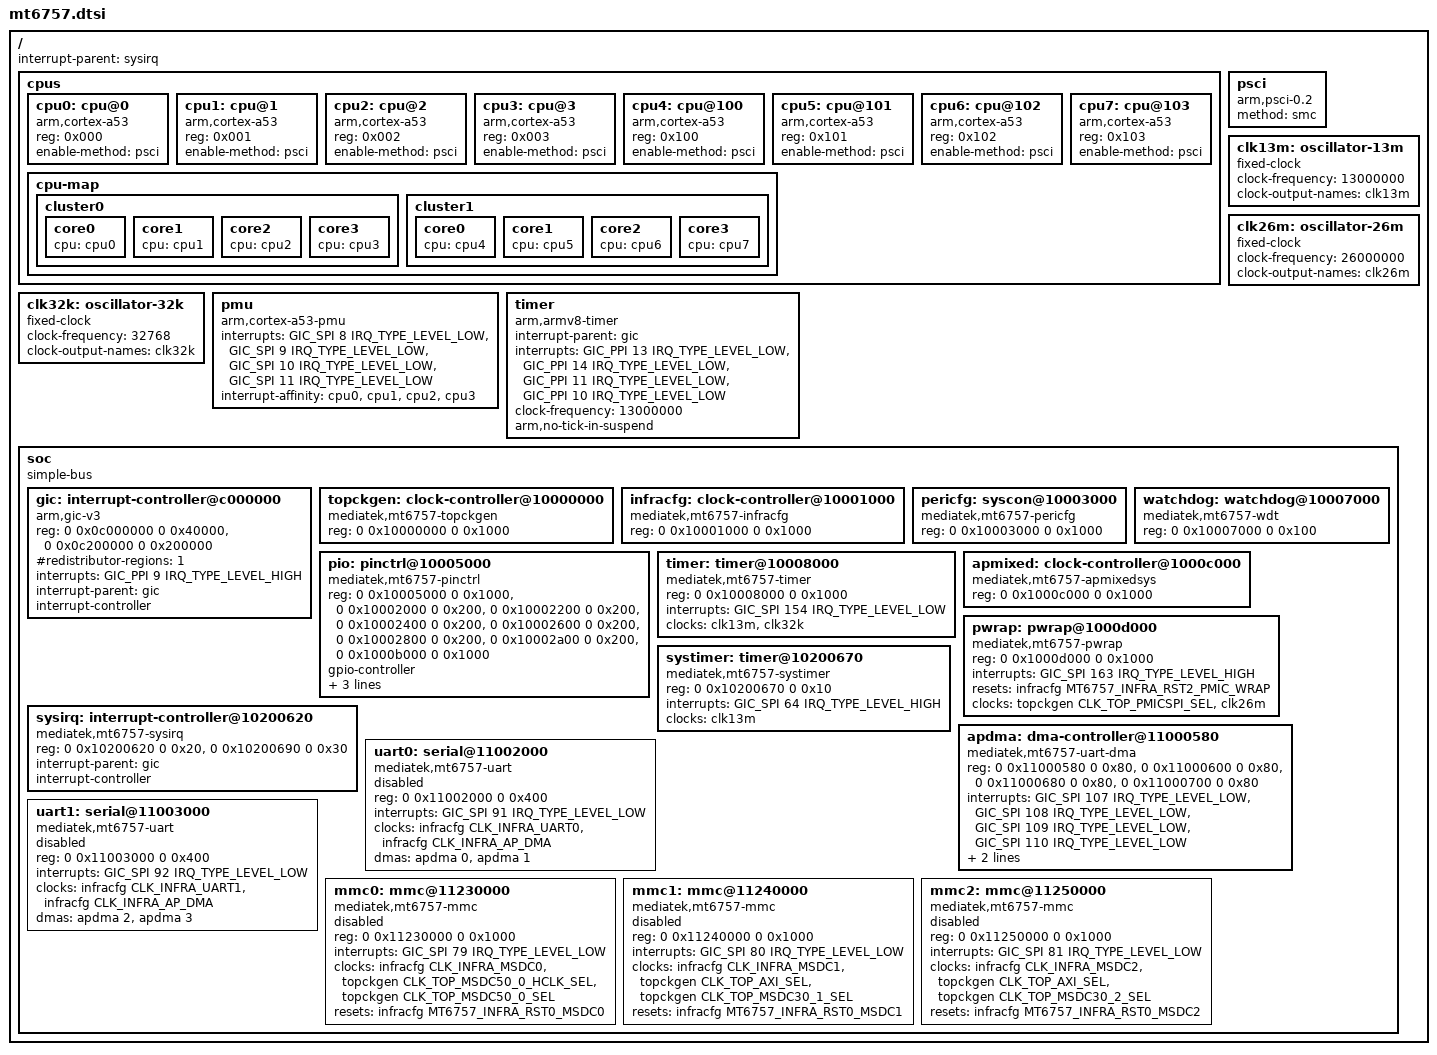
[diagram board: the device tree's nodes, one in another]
// SPDX-License-Identifier: GPL-2.0-only
/*
 * Copyright (c) 2025 Ben Grisdale <bengris32@protonmail.ch>
 */

#include <dt-bindings/interrupt-controller/arm-gic.h>

#include <dt-bindings/clock/mediatek,mt6757-apmixedsys.h>
#include <dt-bindings/clock/mediatek,mt6757-infracfg.h>
#include <dt-bindings/clock/mediatek,mt6757-pericfg.h>
#include <dt-bindings/clock/mediatek,mt6757-topckgen.h>
#include <dt-bindings/pinctrl/mt6757-pinfunc.h>
#include <dt-bindings/reset/mediatek,mt6757-infracfg.h>
#include <dt-bindings/reset/mediatek,mt6757-wdt.h>

/ {
	#address-cells = <2>;
	#size-cells = <2>;
	interrupt-parent = <&sysirq>;

	cpus {
		#address-cells = <1>;
		#size-cells = <0>;

		cpu0: cpu@0 {
			device_type = "cpu";
			compatible = "arm,cortex-a53";
			reg = <0x000>;
			enable-method = "psci";
		};

		cpu1: cpu@1 {
			device_type = "cpu";
			compatible = "arm,cortex-a53";
			reg = <0x001>;
			enable-method = "psci";
		};

		cpu2: cpu@2 {
			device_type = "cpu";
			compatible = "arm,cortex-a53";
			reg = <0x002>;
			enable-method = "psci";
		};

		cpu3: cpu@3 {
			device_type = "cpu";
			compatible = "arm,cortex-a53";
			reg = <0x003>;
			enable-method = "psci";
		};

		cpu4: cpu@100 {
			device_type = "cpu";
			compatible = "arm,cortex-a53";
			reg = <0x100>;
			enable-method = "psci";
		};

		cpu5: cpu@101 {
			device_type = "cpu";
			compatible = "arm,cortex-a53";
			reg = <0x101>;
			enable-method = "psci";
		};

		cpu6: cpu@102 {
			device_type = "cpu";
			compatible = "arm,cortex-a53";
			reg = <0x102>;
			enable-method = "psci";
		};

		cpu7: cpu@103 {
			device_type = "cpu";
			compatible = "arm,cortex-a53";
			reg = <0x103>;
			enable-method = "psci";
		};

		cpu-map {
			cluster0 {
				core0 {
					cpu = <&cpu0>;
				};

				core1 {
					cpu = <&cpu1>;
				};

				core2 {
					cpu = <&cpu2>;
				};

				core3 {
					cpu = <&cpu3>;
				};
			};

			cluster1 {
				core0 {
					cpu = <&cpu4>;
				};

				core1 {
					cpu = <&cpu5>;
				};

				core2 {
					cpu = <&cpu6>;
				};

				core3 {
					cpu = <&cpu7>;
				};
			};
		};
	};

	psci {
		compatible = "arm,psci-0.2";
		method = "smc";
	};

	clk13m: oscillator-13m {
		compatible = "fixed-clock";
		#clock-cells = <0>;
		clock-frequency = <13000000>;
		clock-output-names = "clk13m";
	};

	clk26m: oscillator-26m {
		compatible = "fixed-clock";
		#clock-cells = <0>;
		clock-frequency = <26000000>;
		clock-output-names = "clk26m";
	};

	clk32k: oscillator-32k {
		compatible = "fixed-clock";
		#clock-cells = <0>;
		clock-frequency = <32768>;
		clock-output-names = "clk32k";
	};

	pmu {
		compatible = "arm,cortex-a53-pmu";
		interrupts = <GIC_SPI 8 IRQ_TYPE_LEVEL_LOW>,
			     <GIC_SPI 9 IRQ_TYPE_LEVEL_LOW>,
			     <GIC_SPI 10 IRQ_TYPE_LEVEL_LOW>,
			     <GIC_SPI 11 IRQ_TYPE_LEVEL_LOW>;
		interrupt-affinity = <&cpu0>, <&cpu1>, <&cpu2>, <&cpu3>;
	};

	timer {
		compatible = "arm,armv8-timer";
		interrupt-parent = <&gic>;
		interrupts = <GIC_PPI 13 IRQ_TYPE_LEVEL_LOW>,
			     <GIC_PPI 14 IRQ_TYPE_LEVEL_LOW>,
			     <GIC_PPI 11 IRQ_TYPE_LEVEL_LOW>,
			     <GIC_PPI 10 IRQ_TYPE_LEVEL_LOW>;
		clock-frequency = <13000000>;
		arm,no-tick-in-suspend;
	};

	soc {
		compatible = "simple-bus";
		#address-cells = <2>;
		#size-cells = <2>;
		ranges;

		gic: interrupt-controller@c000000 {
			compatible = "arm,gic-v3";
			reg = <0 0x0c000000 0 0x40000>, /* GICD */
			      <0 0x0c200000 0 0x200000>; /* GICR */
			#interrupt-cells = <3>;
			#redistributor-regions = <1>;
			interrupts = <GIC_PPI 9 IRQ_TYPE_LEVEL_HIGH>;
			interrupt-parent = <&gic>;
			interrupt-controller;
		};

		topckgen: clock-controller@10000000 {
			compatible = "mediatek,mt6757-topckgen", "syscon";
			reg = <0 0x10000000 0 0x1000>;
			#clock-cells = <1>;
		};

		infracfg: clock-controller@10001000 {
			compatible = "mediatek,mt6757-infracfg", "syscon";
			reg = <0 0x10001000 0 0x1000>;
			#clock-cells = <1>;
			#reset-cells = <1>;
		};

		pericfg: syscon@10003000 {
			compatible = "mediatek,mt6757-pericfg", "syscon";
			reg = <0 0x10003000 0 0x1000>;
		};

		pio: pinctrl@10005000 {
			compatible = "mediatek,mt6757-pinctrl";
			reg = <0 0x10005000 0 0x1000>,
			      <0 0x10002000 0 0x200>,
			      <0 0x10002200 0 0x200>,
			      <0 0x10002400 0 0x200>,
			      <0 0x10002600 0 0x200>,
			      <0 0x10002800 0 0x200>,
			      <0 0x10002a00 0 0x200>,
			      <0 0x1000b000 0 0x1000>;
			reg-names = "gpio", "iocfg0", "iocfg1", "iocfg2",
				    "iocfg3", "iocfg4", "iocfg5", "eint";
			gpio-controller;
			#gpio-cells = <2>;
			gpio-ranges = <&pio 0 0 193>;
			interrupts = <GIC_SPI 155 IRQ_TYPE_LEVEL_HIGH>;
			interrupt-controller;
			#interrupt-cells = <2>;
		};

		watchdog: watchdog@10007000 {
			compatible = "mediatek,mt6757-wdt";
			reg = <0 0x10007000 0 0x100>;
			#reset-cells = <1>;
		};

		timer: timer@10008000 {
			compatible = "mediatek,mt6757-timer", "mediatek,mt6577-timer";
			reg = <0 0x10008000 0 0x1000>;
			interrupts = <GIC_SPI 154 IRQ_TYPE_LEVEL_LOW>;
			clocks = <&clk13m>, <&clk32k>;
		};

		apmixed: clock-controller@1000c000 {
			compatible = "mediatek,mt6757-apmixedsys";
			reg = <0 0x1000c000 0 0x1000>;
			#clock-cells = <1>;
		};

		pwrap: pwrap@1000d000 {
			compatible = "mediatek,mt6757-pwrap", "mediatek,mt6797-pwrap";
			reg = <0 0x1000d000 0 0x1000>;
			reg-names = "pwrap";
			interrupts = <GIC_SPI 163 IRQ_TYPE_LEVEL_HIGH>;
			resets = <&infracfg MT6757_INFRA_RST2_PMIC_WRAP>;
			reset-names = "pwrap";
			clocks = <&topckgen CLK_TOP_PMICSPI_SEL>, <&clk26m>;
			clock-names = "spi", "wrap";
		};

		sysirq: interrupt-controller@10200620 {
			compatible = "mediatek,mt6757-sysirq", "mediatek,mt6577-sysirq";
			reg = <0 0x10200620 0 0x20>, /* INT_POL_CTL[0-7] */
			      <0 0x10200690 0 0x30>; /* INT_POL_CTL[8-19] */
			#interrupt-cells = <3>;
			interrupt-parent = <&gic>;
			interrupt-controller;
		};
	
		systimer: timer@10200670 {
			compatible = "mediatek,mt6757-systimer", "mediatek,mt6795-systimer";
			reg = <0 0x10200670 0 0x10>;
			interrupts = <GIC_SPI 64 IRQ_TYPE_LEVEL_HIGH>;
			clocks = <&clk13m>;
			clock-names = "clk13m";
		};

		apdma: dma-controller@11000580 {
			compatible = "mediatek,mt6757-uart-dma", "mediatek,mt6577-uart-dma";
			reg = <0 0x11000580 0 0x80>,
			      <0 0x11000600 0 0x80>,
			      <0 0x11000680 0 0x80>,
			      <0 0x11000700 0 0x80>;
			interrupts = <GIC_SPI 107 IRQ_TYPE_LEVEL_LOW>,
				     <GIC_SPI 108 IRQ_TYPE_LEVEL_LOW>,
				     <GIC_SPI 109 IRQ_TYPE_LEVEL_LOW>,
				     <GIC_SPI 110 IRQ_TYPE_LEVEL_LOW>;
			dma-requests = <4>;
			clocks = <&infracfg CLK_INFRA_AP_DMA>;
			clock-names = "apdma";
			#dma-cells = <1>;
		};

		uart0: serial@11002000 {
			compatible = "mediatek,mt6757-uart", "mediatek,mt6577-uart";
			reg = <0 0x11002000 0 0x400>;
			interrupts = <GIC_SPI 91 IRQ_TYPE_LEVEL_LOW>;
			clocks = <&infracfg CLK_INFRA_UART0>, <&infracfg CLK_INFRA_AP_DMA>;
			clock-names = "baud", "bus";
			dmas = <&apdma 0 &apdma 1>;
			dma-names = "tx", "rx";
			status = "disabled";
		};

		uart1: serial@11003000 {
			compatible = "mediatek,mt6757-uart", "mediatek,mt6577-uart";
			reg = <0 0x11003000 0 0x400>;
			interrupts = <GIC_SPI 92 IRQ_TYPE_LEVEL_LOW>;
			clocks = <&infracfg CLK_INFRA_UART1>, <&infracfg CLK_INFRA_AP_DMA>;
			clock-names = "baud", "bus";
			dmas = <&apdma 2 &apdma 3>;
			dma-names = "tx", "rx";
			status = "disabled";
		};

		mmc0: mmc@11230000 {
			compatible = "mediatek,mt6757-mmc";
			reg = <0 0x11230000 0 0x1000>;
			interrupts = <GIC_SPI 79 IRQ_TYPE_LEVEL_LOW>;
			clocks = <&infracfg CLK_INFRA_MSDC0>,
				 <&topckgen CLK_TOP_MSDC50_0_HCLK_SEL>,
				 <&topckgen CLK_TOP_MSDC50_0_SEL>;
			clock-names = "source", "hclk", "source_cg";
			resets = <&infracfg MT6757_INFRA_RST0_MSDC0>;
			reset-names = "hrst";
			status = "disabled";
		};

		mmc1: mmc@11240000 {
			compatible = "mediatek,mt6757-mmc";
			reg = <0 0x11240000 0 0x1000>;
			interrupts = <GIC_SPI 80 IRQ_TYPE_LEVEL_LOW>;
			clocks = <&infracfg CLK_INFRA_MSDC1>,
				 <&topckgen CLK_TOP_AXI_SEL>,
				 <&topckgen CLK_TOP_MSDC30_1_SEL>;
			clock-names = "source", "hclk", "source_cg";
			resets = <&infracfg MT6757_INFRA_RST0_MSDC1>;
			reset-names = "hrst";
			status = "disabled";
		};

		mmc2: mmc@11250000 {
			compatible = "mediatek,mt6757-mmc";
			reg = <0 0x11250000 0 0x1000>;
			interrupts = <GIC_SPI 81 IRQ_TYPE_LEVEL_LOW>;
			clocks = <&infracfg CLK_INFRA_MSDC2>,
				 <&topckgen CLK_TOP_AXI_SEL>,
				 <&topckgen CLK_TOP_MSDC30_2_SEL>;
			clock-names = "source", "hclk", "source_cg";
			resets = <&infracfg MT6757_INFRA_RST0_MSDC2>;
			reset-names = "hrst";
			status = "disabled";
		};
	};
};
